# RockChip_RK3588 register map
Vendor: RockChip Electronics Co., Ltd.; Series: RK3588; File version: 0.1
Registers are 32-bit, read-write, no defined reset value unless marked. A register's access mark holds for its fields unless they carry their own. Offsets are from the block's base; [hi:lo] are bit positions.

## CRU (part 6 of 6)
Base 0xFD7C0000
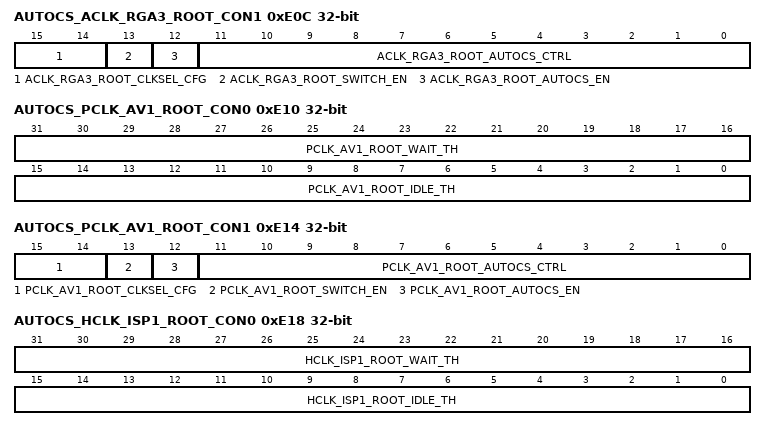
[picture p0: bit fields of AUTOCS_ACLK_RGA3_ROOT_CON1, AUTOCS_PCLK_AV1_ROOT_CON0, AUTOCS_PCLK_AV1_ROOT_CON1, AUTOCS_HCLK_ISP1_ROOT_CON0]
0xE0C AUTOCS_ACLK_RGA3_ROOT_CON1 — Auto clock switch control register 1
  [15:14] ACLK_RGA3_ROOT_CLKSEL_CFG — clksel_cfg Auto switch clock selection.
    0=ORIGINAL_CLK; 1=XIN_OSC0_FUNC_DIV; 2=CLK_RTC_32K
  [13] ACLK_RGA3_ROOT_SWITCH_EN — switch_en
    1=ENABLE (Enable aclk_rga3_root switched to lower frequency when module is inactive.); 0=DISABLE (Disable auto switch function.)
  [12] ACLK_RGA3_ROOT_AUTOCS_EN — autocs_en
    1=ENABLE (Enable aclk_rga3_root switch to lower frequency.); 0=DISABLE
  [11:0] ACLK_RGA3_ROOT_AUTOCS_CTRL — autocs_ctrl. Others: Reserved.
    0xFFF=ENABLE (Enable aclk_rga3_root switch to lower frequency.); 0=DISABLE
0xE10 AUTOCS_PCLK_AV1_ROOT_CON0 — Auto clock switch control register 0
  [31:16] PCLK_AV1_ROOT_WAIT_TH — wait_th. Wait time threshold, measured by original clk.
  [15:0] PCLK_AV1_ROOT_IDLE_TH — idle_th. Idle time threshold, measured by original clk.
0xE14 AUTOCS_PCLK_AV1_ROOT_CON1 — Auto clock switch control register 1
  [15:14] PCLK_AV1_ROOT_CLKSEL_CFG — clksel_cfg Auto switch clock selection.
    0=ORIGINAL_CLK; 1=XIN_OSC0_FUNC_DIV; 2=CLK_RTC_32K
  [13] PCLK_AV1_ROOT_SWITCH_EN — switch_en
    1=ENABLE (Enable pclk_av1_root switched to lower frequency when module is inactive.); 0=DISABLE (Disable auto switch function.)
  [12] PCLK_AV1_ROOT_AUTOCS_EN — autocs_en
    1=ENABLE (Enable pclk_av1_root switch to lower frequency.); 0=DISABLE
  [11:0] PCLK_AV1_ROOT_AUTOCS_CTRL — autocs_ctrl. Others: Reserved.
    0xFFF=ENABLE (Enable pclk_av1_root switch to lower frequency.); 0=DISABLE
0xE18 AUTOCS_HCLK_ISP1_ROOT_CON0 — Auto clock switch control register 0
  [31:16] HCLK_ISP1_ROOT_WAIT_TH — wait_th. Wait time threshold, measured by original clk.
  [15:0] HCLK_ISP1_ROOT_IDLE_TH — idle_th. Idle time threshold, measured by original clk.
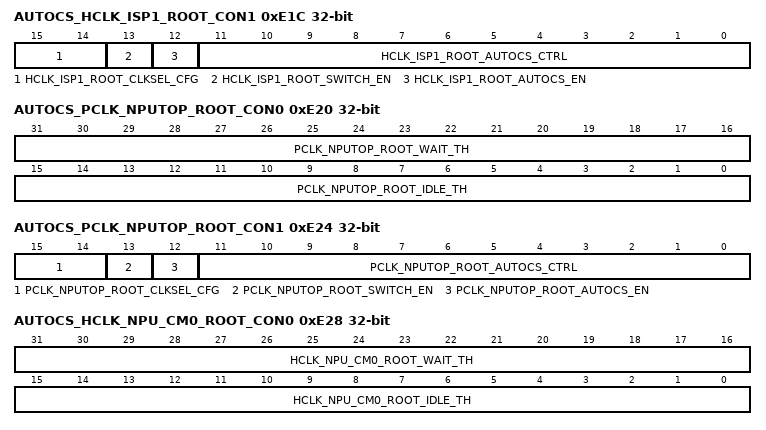
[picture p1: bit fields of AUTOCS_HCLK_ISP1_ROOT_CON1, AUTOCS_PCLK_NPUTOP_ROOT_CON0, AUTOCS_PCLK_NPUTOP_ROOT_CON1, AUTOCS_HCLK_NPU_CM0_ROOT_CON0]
0xE1C AUTOCS_HCLK_ISP1_ROOT_CON1 — Auto clock switch control register 1
  [15:14] HCLK_ISP1_ROOT_CLKSEL_CFG — clksel_cfg Auto switch clock selection.
    0=ORIGINAL_CLK; 1=XIN_OSC0_FUNC_DIV; 2=CLK_RTC_32K
  [13] HCLK_ISP1_ROOT_SWITCH_EN — switch_en
    1=ENABLE (Enable hclk_isp1_root switched to lower frequency when module is inactive.); 0=DISABLE (Disable auto switch function.)
  [12] HCLK_ISP1_ROOT_AUTOCS_EN — autocs_en
    1=ENABLE (Enable hclk_isp1_root switch to lower frequency.); 0=DISABLE
  [11:0] HCLK_ISP1_ROOT_AUTOCS_CTRL — autocs_ctrl. Others: Reserved.
    0xFFF=ENABLE (Enable hclk_isp1_root switch to lower frequency.); 0=DISABLE
0xE20 AUTOCS_PCLK_NPUTOP_ROOT_CON0 — Auto clock switch control register 0
  [31:16] PCLK_NPUTOP_ROOT_WAIT_TH — wait_th. Wait time threshold, measured by original clk.
  [15:0] PCLK_NPUTOP_ROOT_IDLE_TH — idle_th. Idle time threshold, measured by original clk.
0xE24 AUTOCS_PCLK_NPUTOP_ROOT_CON1 — Auto clock switch control register 1
  [15:14] PCLK_NPUTOP_ROOT_CLKSEL_CFG — clksel_cfg Auto switch clock selection.
    0=ORIGINAL_CLK; 1=XIN_OSC0_FUNC_DIV; 2=CLK_RTC_32K
  [13] PCLK_NPUTOP_ROOT_SWITCH_EN — switch_en
    1=ENABLE (Enable pclk_nputop_root switched to lower frequency when module is inactive.); 0=DISABLE (Disable auto switch function.)
  [12] PCLK_NPUTOP_ROOT_AUTOCS_EN — autocs_en
    1=ENABLE (Enable pclk_nputop_root switch to lower frequency.); 0=DISABLE
  [11:0] PCLK_NPUTOP_ROOT_AUTOCS_CTRL — autocs_ctrl. Others: Reserved.
    0xFFF=ENABLE (Enable pclk_nputop_root switch to lower frequency.); 0=DISABLE
0xE28 AUTOCS_HCLK_NPU_CM0_ROOT_CON0 — Auto clock switch control register 0
  [31:16] HCLK_NPU_CM0_ROOT_WAIT_TH — wait_th. Wait time threshold, measured by original clk.
  [15:0] HCLK_NPU_CM0_ROOT_IDLE_TH — idle_th. Idle time threshold, measured by original clk.
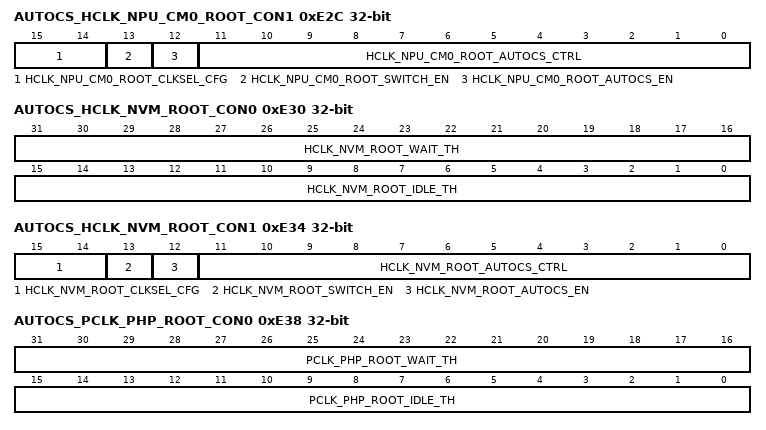
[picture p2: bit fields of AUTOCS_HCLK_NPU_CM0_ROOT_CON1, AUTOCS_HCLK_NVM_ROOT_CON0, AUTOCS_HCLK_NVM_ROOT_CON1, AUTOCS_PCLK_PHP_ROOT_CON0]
0xE2C AUTOCS_HCLK_NPU_CM0_ROOT_CON1 — Auto clock switch control register 1
  [15:14] HCLK_NPU_CM0_ROOT_CLKSEL_CFG — clksel_cfg Auto switch clock selection.
    0=ORIGINAL_CLK; 1=XIN_OSC0_FUNC_DIV; 2=CLK_RTC_32K
  [13] HCLK_NPU_CM0_ROOT_SWITCH_EN — switch_en
    1=ENABLE (Enable hclk_npu_cm0_root switched to lower frequency when module is inactive.); 0=DISABLE (Disable auto switch function.)
  [12] HCLK_NPU_CM0_ROOT_AUTOCS_EN — autocs_en
    1=ENABLE (Enable hclk_npu_cm0_root switch to lower frequency.); 0=DISABLE
  [11:0] HCLK_NPU_CM0_ROOT_AUTOCS_CTRL — autocs_ctrl. Others: Reserved.
    0xFFF=ENABLE (Enable hclk_npu_cm0_root switch to lower frequency.); 0=DISABLE
0xE30 AUTOCS_HCLK_NVM_ROOT_CON0 — Auto clock switch control register 0
  [31:16] HCLK_NVM_ROOT_WAIT_TH — wait_th. Wait time threshold, measured by original clk.
  [15:0] HCLK_NVM_ROOT_IDLE_TH — idle_th. Idle time threshold, measured by original clk.
0xE34 AUTOCS_HCLK_NVM_ROOT_CON1 — Auto clock switch control register 1
  [15:14] HCLK_NVM_ROOT_CLKSEL_CFG — clksel_cfg Auto switch clock selection.
    0=ORIGINAL_CLK; 1=XIN_OSC0_FUNC_DIV; 2=CLK_RTC_32K
  [13] HCLK_NVM_ROOT_SWITCH_EN — switch_en
    1=ENABLE (Enable hclk_nvm_root switched to lower frequency when module is inactive.); 0=DISABLE (Disable auto switch function.)
  [12] HCLK_NVM_ROOT_AUTOCS_EN — autocs_en
    1=ENABLE (Enable hclk_nvm_root switch to lower frequency.); 0=DISABLE
  [11:0] HCLK_NVM_ROOT_AUTOCS_CTRL — autocs_ctrl. Others: Reserved.
    0xFFF=ENABLE (Enable hclk_nvm_root switch to lower frequency.); 0=DISABLE
0xE38 AUTOCS_PCLK_PHP_ROOT_CON0 — Auto clock switch control register 0
  [31:16] PCLK_PHP_ROOT_WAIT_TH — wait_th. Wait time threshold, measured by original clk.
  [15:0] PCLK_PHP_ROOT_IDLE_TH — idle_th. Idle time threshold, measured by original clk.
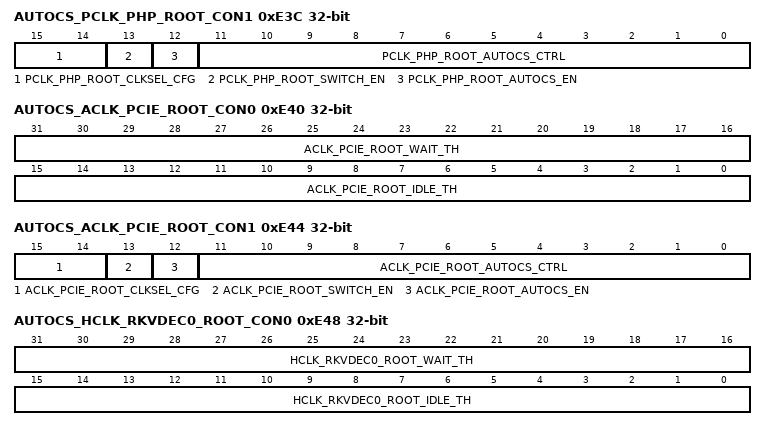
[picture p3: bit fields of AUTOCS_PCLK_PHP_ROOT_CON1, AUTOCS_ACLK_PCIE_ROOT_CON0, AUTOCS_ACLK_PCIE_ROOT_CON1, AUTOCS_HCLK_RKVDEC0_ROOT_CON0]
0xE3C AUTOCS_PCLK_PHP_ROOT_CON1 — Auto clock switch control register 1
  [15:14] PCLK_PHP_ROOT_CLKSEL_CFG — clksel_cfg Auto switch clock selection.
    0=ORIGINAL_CLK; 1=XIN_OSC0_FUNC_DIV; 2=CLK_RTC_32K
  [13] PCLK_PHP_ROOT_SWITCH_EN — switch_en
    1=ENABLE (Enable pclk_php_root switched to lower frequency when module is inactive.); 0=DISABLE (Disable auto switch function.)
  [12] PCLK_PHP_ROOT_AUTOCS_EN — autocs_en
    1=ENABLE (Enable pclk_php_root switch to lower frequency.); 0=DISABLE
  [11:0] PCLK_PHP_ROOT_AUTOCS_CTRL — autocs_ctrl. Others: Reserved.
    0xFFF=ENABLE (Enable pclk_php_root switch to lower frequency.); 0=DISABLE
0xE40 AUTOCS_ACLK_PCIE_ROOT_CON0 — Auto clock switch control register 0
  [31:16] ACLK_PCIE_ROOT_WAIT_TH — wait_th. Wait time threshold, measured by original clk.
  [15:0] ACLK_PCIE_ROOT_IDLE_TH — idle_th. Idle time threshold, measured by original clk.
0xE44 AUTOCS_ACLK_PCIE_ROOT_CON1 — Auto clock switch control register 1
  [15:14] ACLK_PCIE_ROOT_CLKSEL_CFG — clksel_cfg Auto switch clock selection.
    0=ORIGINAL_CLK; 1=XIN_OSC0_FUNC_DIV; 2=CLK_RTC_32K
  [13] ACLK_PCIE_ROOT_SWITCH_EN — switch_en
    1=ENABLE (Enable aclk_pcie_root switched to lower frequency when module is inactive.); 0=DISABLE (Disable auto switch function.)
  [12] ACLK_PCIE_ROOT_AUTOCS_EN — autocs_en
    1=ENABLE (Enable aclk_pcie_root switch to lower frequency.); 0=DISABLE
  [11:0] ACLK_PCIE_ROOT_AUTOCS_CTRL — autocs_ctrl. Others: Reserved.
    0xFFF=ENABLE (Enable aclk_pcie_root switch to lower frequency.); 0=DISABLE
0xE48 AUTOCS_HCLK_RKVDEC0_ROOT_CON0 — Auto clock switch control register 0CLK_PCIE_ROOT_CLKSEL_CFG ; clksel_cfg Auto switch clock selection.
  [31:16] HCLK_RKVDEC0_ROOT_WAIT_TH — wait_th. Wait time threshold, measured by original clk.
  [15:0] HCLK_RKVDEC0_ROOT_IDLE_TH — idle_th. Idle time threshold, measured by original clk.
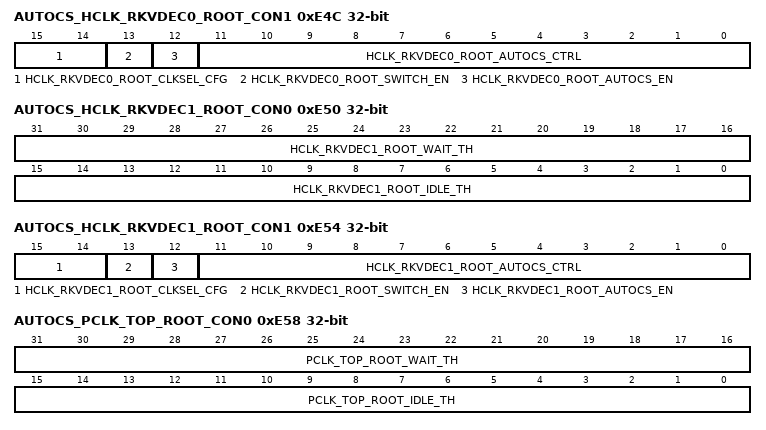
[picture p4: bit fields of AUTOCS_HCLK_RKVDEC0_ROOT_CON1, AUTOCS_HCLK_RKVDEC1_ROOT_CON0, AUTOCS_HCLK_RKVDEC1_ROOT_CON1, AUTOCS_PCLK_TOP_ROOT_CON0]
0xE4C AUTOCS_HCLK_RKVDEC0_ROOT_CON1 — Auto clock switch control register 1
  [15:14] HCLK_RKVDEC0_ROOT_CLKSEL_CFG — clksel_cfg Auto switch clock selection.
    0=ORIGINAL_CLK; 1=XIN_OSC0_FUNC_DIV; 2=CLK_RTC_32K
  [13] HCLK_RKVDEC0_ROOT_SWITCH_EN — switch_en
    1=ENABLE (Enable hclk_rkvdec0_root switched to lower frequency when module is inactive.); 0=DISABLE (Disable auto switch function.)
  [12] HCLK_RKVDEC0_ROOT_AUTOCS_EN — autocs_en
    1=ENABLE (Enable hclk_rkvdec0_root switch to lower frequency.); 0=DISABLE
  [11:0] HCLK_RKVDEC0_ROOT_AUTOCS_CTRL — autocs_ctrl. Others: Reserved.
    0xFFF=ENABLE (Enable hclk_rkvdec0_root switch to lower frequency.); 0=DISABLE
0xE50 AUTOCS_HCLK_RKVDEC1_ROOT_CON0 — Auto clock switch control register 0
  [31:16] HCLK_RKVDEC1_ROOT_WAIT_TH — wait_th. Wait time threshold, measured by original clk.
  [15:0] HCLK_RKVDEC1_ROOT_IDLE_TH — idle_th. Idle time threshold, measured by original clk.
0xE54 AUTOCS_HCLK_RKVDEC1_ROOT_CON1 — Auto clock switch control register 1
  [15:14] HCLK_RKVDEC1_ROOT_CLKSEL_CFG — clksel_cfg Auto switch clock selection.
    0=ORIGINAL_CLK; 1=XIN_OSC0_FUNC_DIV; 2=CLK_RTC_32K
  [13] HCLK_RKVDEC1_ROOT_SWITCH_EN — switch_en
    1=ENABLE (Enable hclk_rkvdec1_root switched to lower frequency when module is inactive.); 0=DISABLE (Disable auto switch function.)
  [12] HCLK_RKVDEC1_ROOT_AUTOCS_EN — autocs_en
    1=ENABLE (Enable hclk_rkvdec1_root switch to lower frequency.); 0=DISABLE
  [11:0] HCLK_RKVDEC1_ROOT_AUTOCS_CTRL — autocs_ctrl. Others: Reserved.
    0xFFF=ENABLE (Enable hclk_rkvdec1_root switch to lower frequency.); 0=DISABLE
0xE58 AUTOCS_PCLK_TOP_ROOT_CON0 — Auto clock switch control register 0
  [31:16] PCLK_TOP_ROOT_WAIT_TH — wait_th. Wait time threshold, measured by original clk.
  [15:0] PCLK_TOP_ROOT_IDLE_TH — idle_th. Idle time threshold, measured by original clk.
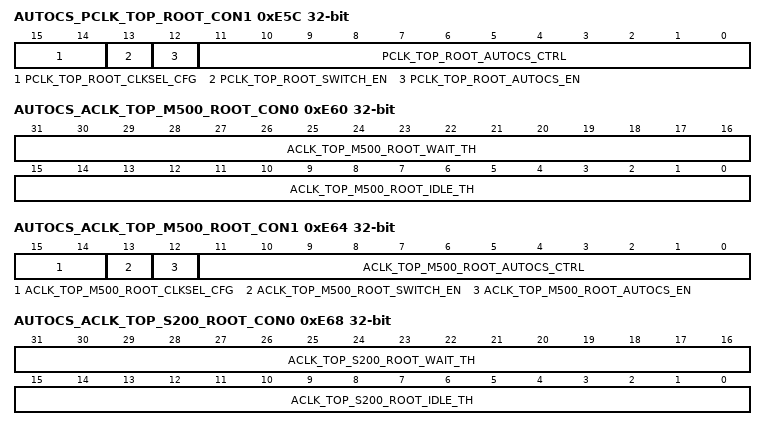
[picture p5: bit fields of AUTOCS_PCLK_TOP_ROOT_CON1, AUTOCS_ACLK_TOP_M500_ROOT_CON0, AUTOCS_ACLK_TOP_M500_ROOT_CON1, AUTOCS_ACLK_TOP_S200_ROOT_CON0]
0xE5C AUTOCS_PCLK_TOP_ROOT_CON1 — Auto clock switch control register 1
  [15:14] PCLK_TOP_ROOT_CLKSEL_CFG — clksel_cfg Auto switch clock selection.
    0=ORIGINAL_CLK; 1=XIN_OSC0_FUNC_DIV; 2=CLK_RTC_32K
  [13] PCLK_TOP_ROOT_SWITCH_EN — switch_en
    1=ENABLE (Enable pclk_top_root switched to lower frequency when module is inactive.); 0=DISABLE (Disable auto switch function.)
  [12] PCLK_TOP_ROOT_AUTOCS_EN — autocs_en
    1=ENABLE (Enable pclk_top_root switch to lower frequency.); 0=DISABLE
  [11:0] PCLK_TOP_ROOT_AUTOCS_CTRL — autocs_ctrl. Others: Reserved.
    0xFFF=ENABLE (Enable pclk_top_root switch to lower frequency.); 0=DISABLE
0xE60 AUTOCS_ACLK_TOP_M500_ROOT_CON0 — Auto clock switch control register 0
  [31:16] ACLK_TOP_M500_ROOT_WAIT_TH — wait_th. Wait time threshold, measured by original clk.
  [15:0] ACLK_TOP_M500_ROOT_IDLE_TH — idle_th. Idle time threshold, measured by original clk.
0xE64 AUTOCS_ACLK_TOP_M500_ROOT_CON1 — Auto clock switch control register 1
  [15:14] ACLK_TOP_M500_ROOT_CLKSEL_CFG — clksel_cfg Auto switch clock selection.
    0=ORIGINAL_CLK; 1=XIN_OSC0_FUNC_DIV; 2=CLK_RTC_32K
  [13] ACLK_TOP_M500_ROOT_SWITCH_EN — switch_en
    1=ENABLE (Enable aclk_top_m500_root switched to lower frequency when module is inactive.); 0=DISABLE (Disable auto switch function.)
  [12] ACLK_TOP_M500_ROOT_AUTOCS_EN — autocs_en
    1=ENABLE (Enable aclk_top_m500_root switch to lower frequency.); 0=DISABLE
  [11:0] ACLK_TOP_M500_ROOT_AUTOCS_CTRL — autocs_ctrl. Others: Reserved.
    0xFFF=ENABLE (Enable aclk_top_m500_root switch to lower frequency.); 0=DISABLE
0xE68 AUTOCS_ACLK_TOP_S200_ROOT_CON0 — Auto clock switch control register 0
  [31:16] ACLK_TOP_S200_ROOT_WAIT_TH — wait_th. Wait time threshold, measured by original clk.
  [15:0] ACLK_TOP_S200_ROOT_IDLE_TH — idle_th. Idle time threshold, measured by original clk.
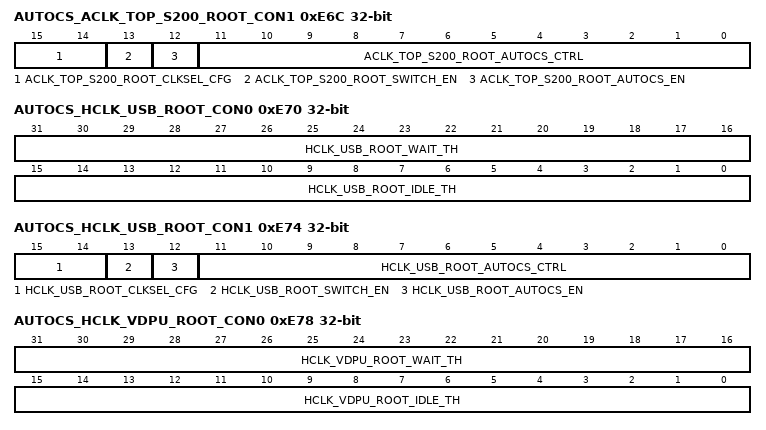
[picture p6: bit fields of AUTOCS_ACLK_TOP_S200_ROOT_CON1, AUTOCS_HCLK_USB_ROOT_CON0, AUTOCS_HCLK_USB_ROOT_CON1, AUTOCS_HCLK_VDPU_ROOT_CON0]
0xE6C AUTOCS_ACLK_TOP_S200_ROOT_CON1 — Auto clock switch control register 1
  [15:14] ACLK_TOP_S200_ROOT_CLKSEL_CFG — clksel_cfg Auto switch clock selection.
    0=ORIGINAL_CLK; 1=XIN_OSC0_FUNC_DIV; 2=CLK_RTC_32K
  [13] ACLK_TOP_S200_ROOT_SWITCH_EN — switch_en
    1=ENABLE (Enable aclk_top_s200_root switched to lower frequency when module is inactive.); 0=DISABLE (Disable auto switch function.)
  [12] ACLK_TOP_S200_ROOT_AUTOCS_EN — autocs_en
    1=ENABLE (Enable aclk_top_s200_root switch to lower frequency.); 0=DISABLE
  [11:0] ACLK_TOP_S200_ROOT_AUTOCS_CTRL — autocs_ctrl. Others: Reserved.
    0xFFF=ENABLE (Enable aclk_top_s200_root switch to lower frequency.); 0=DISABLE
0xE70 AUTOCS_HCLK_USB_ROOT_CON0 — Auto clock switch control register 0
  [31:16] HCLK_USB_ROOT_WAIT_TH — wait_th. Wait time threshold, measured by original clk.
  [15:0] HCLK_USB_ROOT_IDLE_TH — idle_th. Idle time threshold, measured by original clk.
0xE74 AUTOCS_HCLK_USB_ROOT_CON1 — Auto clock switch control register 1
  [15:14] HCLK_USB_ROOT_CLKSEL_CFG — clksel_cfg Auto switch clock selection.
    0=ORIGINAL_CLK; 1=XIN_OSC0_FUNC_DIV; 2=CLK_RTC_32K
  [13] HCLK_USB_ROOT_SWITCH_EN — switch_en
    1=ENABLE (Enable hclk_usb_root switched to lower frequency when module is inactive.); 0=DISABLE (Disable auto switch function.)
  [12] HCLK_USB_ROOT_AUTOCS_EN — autocs_en
    1=ENABLE (Enable hclk_usb_root switch to lower frequency.); 0=DISABLE
  [11:0] HCLK_USB_ROOT_AUTOCS_CTRL — autocs_ctrl. Others: Reserved.
    0xFFF=ENABLE (Enable hclk_usb_root switch to lower frequency.); 0=DISABLE
0xE78 AUTOCS_HCLK_VDPU_ROOT_CON0 — Auto clock switch control register 0
  [31:16] HCLK_VDPU_ROOT_WAIT_TH — wait_th. Wait time threshold, measured by original clk.
  [15:0] HCLK_VDPU_ROOT_IDLE_TH — idle_th. Idle time threshold, measured by original clk.
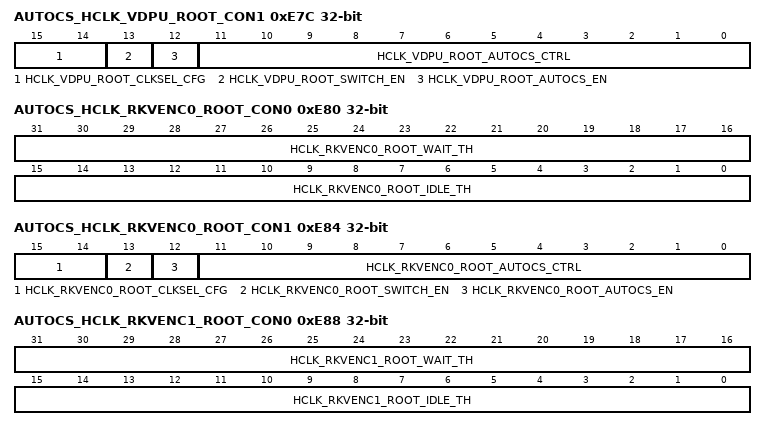
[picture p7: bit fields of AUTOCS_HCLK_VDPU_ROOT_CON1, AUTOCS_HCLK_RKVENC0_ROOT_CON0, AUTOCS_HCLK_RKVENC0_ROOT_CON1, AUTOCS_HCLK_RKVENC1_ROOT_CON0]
0xE7C AUTOCS_HCLK_VDPU_ROOT_CON1 — Auto clock switch control register 1
  [15:14] HCLK_VDPU_ROOT_CLKSEL_CFG — clksel_cfg Auto switch clock selection.
    0=ORIGINAL_CLK; 1=XIN_OSC0_FUNC_DIV; 2=CLK_RTC_32K
  [13] HCLK_VDPU_ROOT_SWITCH_EN — switch_en
    1=ENABLE (Enable hclk_vdpu_root switched to lower frequency when module is inactive.); 0=DISABLE (Disable auto switch function.)
  [12] HCLK_VDPU_ROOT_AUTOCS_EN — autocs_en
    1=ENABLE (Enable hclk_vdpu_root switch to lower frequency.); 0=DISABLE
  [11:0] HCLK_VDPU_ROOT_AUTOCS_CTRL — autocs_ctrl. Others: Reserved.
    0xFFF=ENABLE (Enable hclk_vdpu_root switch to lower frequency.); 0=DISABLE
0xE80 AUTOCS_HCLK_RKVENC0_ROOT_CON0 — Auto clock switch control register 0
  [31:16] HCLK_RKVENC0_ROOT_WAIT_TH — wait_th. Wait time threshold, measured by original clk.
  [15:0] HCLK_RKVENC0_ROOT_IDLE_TH — idle_th. Idle time threshold, measured by original clk.
0xE84 AUTOCS_HCLK_RKVENC0_ROOT_CON1 — Auto clock switch control register 1
  [15:14] HCLK_RKVENC0_ROOT_CLKSEL_CFG — clksel_cfg Auto switch clock selection.
    0=ORIGINAL_CLK; 1=XIN_OSC0_FUNC_DIV; 2=CLK_RTC_32K
  [13] HCLK_RKVENC0_ROOT_SWITCH_EN — switch_en
    1=ENABLE (Enable hclk_rkvenc0_root switched to lower frequency when module is inactive.); 0=DISABLE (Disable auto switch function.)
  [12] HCLK_RKVENC0_ROOT_AUTOCS_EN — autocs_en
    1=ENABLE (Enable hclk_rkvenc0_root switch to lower frequency.); 0=DISABLE
  [11:0] HCLK_RKVENC0_ROOT_AUTOCS_CTRL — autocs_ctrl. Others: Reserved.
    0xFFF=ENABLE (Enable hclk_rkvenc0_root switch to lower frequency.); 0=DISABLE
0xE88 AUTOCS_HCLK_RKVENC1_ROOT_CON0 — Auto clock switch control register 0
  [31:16] HCLK_RKVENC1_ROOT_WAIT_TH — wait_th. Wait time threshold, measured by original clk.
  [15:0] HCLK_RKVENC1_ROOT_IDLE_TH — idle_th. Idle time threshold, measured by original clk.
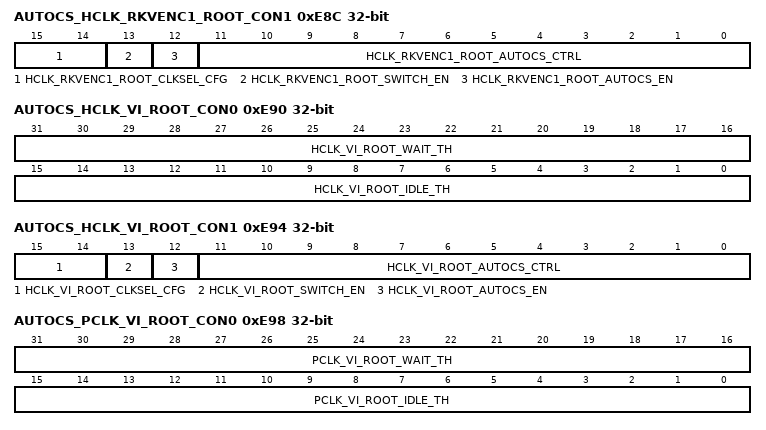
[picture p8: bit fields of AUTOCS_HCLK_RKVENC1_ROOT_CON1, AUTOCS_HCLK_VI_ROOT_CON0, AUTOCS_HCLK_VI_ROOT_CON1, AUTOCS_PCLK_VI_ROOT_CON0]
0xE8C AUTOCS_HCLK_RKVENC1_ROOT_CON1 — Auto clock switch control register 1
  [15:14] HCLK_RKVENC1_ROOT_CLKSEL_CFG — clksel_cfg Auto switch clock selection.
    0=ORIGINAL_CLK; 1=XIN_OSC0_FUNC_DIV; 2=CLK_RTC_32K
  [13] HCLK_RKVENC1_ROOT_SWITCH_EN — switch_en
    1=ENABLE (Enable hclk_rkvenc1_root switched to lower frequency when module is inactive.); 0=DISABLE (Disable auto switch function.)
  [12] HCLK_RKVENC1_ROOT_AUTOCS_EN — autocs_en
    1=ENABLE (Enable hclk_rkvenc1_root switch to lower frequency.); 0=DISABLE
  [11:0] HCLK_RKVENC1_ROOT_AUTOCS_CTRL — autocs_ctrl. Others: Reserved.
    0xFFF=ENABLE (Enable hclk_rkvenc1_root switch to lower frequency.); 0=DISABLE
0xE90 AUTOCS_HCLK_VI_ROOT_CON0 — Auto clock switch control register 0
  [31:16] HCLK_VI_ROOT_WAIT_TH — wait_th. Wait time threshold, measured by original clk.
  [15:0] HCLK_VI_ROOT_IDLE_TH — idle_th. Idle time threshold, measured by original clk.
0xE94 AUTOCS_HCLK_VI_ROOT_CON1 — Auto clock switch control register 1
  [15:14] HCLK_VI_ROOT_CLKSEL_CFG — clksel_cfg Auto switch clock selection.
    0=ORIGINAL_CLK; 1=XIN_OSC0_FUNC_DIV; 2=CLK_RTC_32K
  [13] HCLK_VI_ROOT_SWITCH_EN — switch_en
    1=ENABLE (Enable hclk_vi_root switched to lower frequency when module is inactive.); 0=DISABLE (Disable auto switch function.)
  [12] HCLK_VI_ROOT_AUTOCS_EN — autocs_en
    1=ENABLE (Enable hclk_vi_root switch to lower frequency.); 0=DISABLE
  [11:0] HCLK_VI_ROOT_AUTOCS_CTRL — autocs_ctrl. Others: Reserved.
    0xFFF=ENABLE (Enable hclk_vi_root switch to lower frequency.); 0=DISABLE
0xE98 AUTOCS_PCLK_VI_ROOT_CON0 — Auto clock switch control register 0
  [31:16] PCLK_VI_ROOT_WAIT_TH — wait_th. Wait time threshold, measured by original clk.
  [15:0] PCLK_VI_ROOT_IDLE_TH — idle_th. Idle time threshold, measured by original clk.
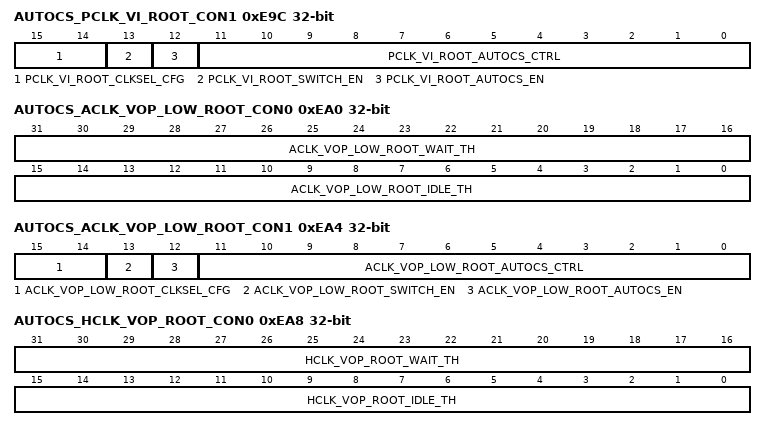
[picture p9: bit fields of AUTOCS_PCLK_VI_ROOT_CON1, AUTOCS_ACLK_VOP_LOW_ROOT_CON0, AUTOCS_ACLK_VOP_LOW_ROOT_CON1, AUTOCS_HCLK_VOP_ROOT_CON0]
0xE9C AUTOCS_PCLK_VI_ROOT_CON1 — Auto clock switch control register 1
  [15:14] PCLK_VI_ROOT_CLKSEL_CFG — clksel_cfg Auto switch clock selection.
    0=ORIGINAL_CLK; 1=XIN_OSC0_FUNC_DIV; 2=CLK_RTC_32K
  [13] PCLK_VI_ROOT_SWITCH_EN — switch_en
    1=ENABLE (Enable pclk_vi_root switched to lower frequency when module is inactive.); 0=DISABLE (Disable auto switch function.)
  [12] PCLK_VI_ROOT_AUTOCS_EN — autocs_en
    1=ENABLE (Enable pclk_vi_root switch to lower frequency.); 0=DISABLE
  [11:0] PCLK_VI_ROOT_AUTOCS_CTRL — autocs_ctrl. Others: Reserved.
    0xFFF=ENABLE (Enable pclk_vi_root switch to lower frequency.); 0=DISABLE
0xEA0 AUTOCS_ACLK_VOP_LOW_ROOT_CON0 — Auto clock switch control register 0
  [31:16] ACLK_VOP_LOW_ROOT_WAIT_TH — wait_th. Wait time threshold, measured by original clk.
  [15:0] ACLK_VOP_LOW_ROOT_IDLE_TH — idle_th. Idle time threshold, measured by original clk.
0xEA4 AUTOCS_ACLK_VOP_LOW_ROOT_CON1 — Auto clock switch control register 1
  [15:14] ACLK_VOP_LOW_ROOT_CLKSEL_CFG — clksel_cfg Auto switch clock selection.
    0=ORIGINAL_CLK; 1=XIN_OSC0_FUNC_DIV; 2=CLK_RTC_32K
  [13] ACLK_VOP_LOW_ROOT_SWITCH_EN — switch_en
    1=ENABLE (Enable aclk_vop_low_root switched to lower frequency when module is inactive.); 0=DISABLE (Disable auto switch function.)
  [12] ACLK_VOP_LOW_ROOT_AUTOCS_EN — autocs_en
    1=ENABLE (Enable aclk_vop_low_root switch to lower frequency.); 0=DISABLE
  [11:0] ACLK_VOP_LOW_ROOT_AUTOCS_CTRL — autocs_ctrl. Others: Reserved.
    0xFFF=ENABLE (Enable aclk_vop_low_root switch to lower frequency.); 0=DISABLE
0xEA8 AUTOCS_HCLK_VOP_ROOT_CON0 — Auto clock switch control register 0
  [31:16] HCLK_VOP_ROOT_WAIT_TH — wait_th. Wait time threshold, measured by original clk.
  [15:0] HCLK_VOP_ROOT_IDLE_TH — idle_th. Idle time threshold, measured by original clk.
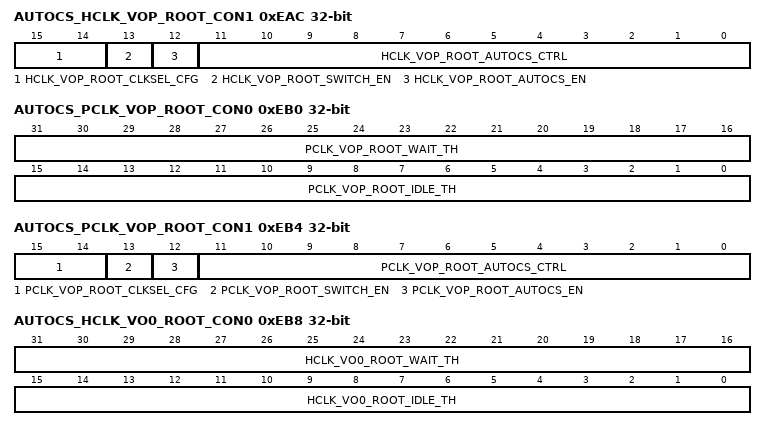
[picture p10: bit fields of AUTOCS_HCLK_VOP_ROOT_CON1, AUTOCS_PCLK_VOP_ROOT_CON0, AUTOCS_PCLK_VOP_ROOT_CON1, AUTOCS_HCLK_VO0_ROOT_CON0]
0xEAC AUTOCS_HCLK_VOP_ROOT_CON1 — Auto clock switch control register 1
  [15:14] HCLK_VOP_ROOT_CLKSEL_CFG — clksel_cfg Auto switch clock selection.
    0=ORIGINAL_CLK; 1=XIN_OSC0_FUNC_DIV; 2=CLK_RTC_32K
  [13] HCLK_VOP_ROOT_SWITCH_EN — switch_en
    1=ENABLE (Enable hclk_vop_root switched to lower frequency when module is inactive.); 0=DISABLE (Disable auto switch function.)
  [12] HCLK_VOP_ROOT_AUTOCS_EN — autocs_en
    1=ENABLE (Enable hclk_vop_root switch to lower frequency.); 0=DISABLE
  [11:0] HCLK_VOP_ROOT_AUTOCS_CTRL — autocs_ctrl. Others: Reserved.
    0xFFF=ENABLE (Enable hclk_vop_root switch to lower frequency.); 0=DISABLE
0xEB0 AUTOCS_PCLK_VOP_ROOT_CON0 — Auto clock switch control register 0
  [31:16] PCLK_VOP_ROOT_WAIT_TH — wait_th. Wait time threshold, measured by original clk.
  [15:0] PCLK_VOP_ROOT_IDLE_TH — idle_th. Idle time threshold, measured by original clk.
0xEB4 AUTOCS_PCLK_VOP_ROOT_CON1 — Auto clock switch control register 1
  [15:14] PCLK_VOP_ROOT_CLKSEL_CFG — clksel_cfg Auto switch clock selection.
    0=ORIGINAL_CLK; 1=XIN_OSC0_FUNC_DIV; 2=CLK_RTC_32K
  [13] PCLK_VOP_ROOT_SWITCH_EN — switch_en
    1=ENABLE (Enable pclk_vop_root switched to lower frequency when module is inactive.); 0=DISABLE (Disable auto switch function.)
  [12] PCLK_VOP_ROOT_AUTOCS_EN — autocs_en
    1=ENABLE (Enable pclk_vop_root switch to lower frequency.); 0=DISABLE
  [11:0] PCLK_VOP_ROOT_AUTOCS_CTRL — autocs_ctrl. Others: Reserved.
    0xFFF=ENABLE (Enable pclk_vop_root switch to lower frequency.); 0=DISABLE
0xEB8 AUTOCS_HCLK_VO0_ROOT_CON0 — Auto clock switch control register 0
  [31:16] HCLK_VO0_ROOT_WAIT_TH — wait_th. Wait time threshold, measured by original clk.
  [15:0] HCLK_VO0_ROOT_IDLE_TH — idle_th. Idle time threshold, measured by original clk.
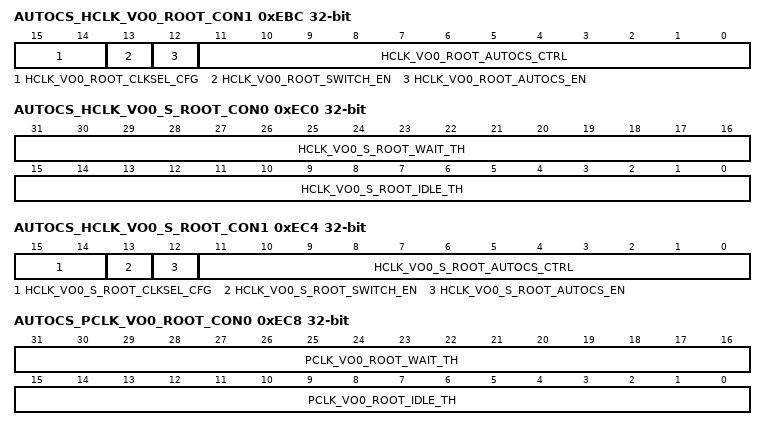
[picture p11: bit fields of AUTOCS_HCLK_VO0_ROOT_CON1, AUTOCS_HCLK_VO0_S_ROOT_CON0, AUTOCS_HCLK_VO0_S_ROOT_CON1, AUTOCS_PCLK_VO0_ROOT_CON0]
0xEBC AUTOCS_HCLK_VO0_ROOT_CON1 — Auto clock switch control register 1
  [15:14] HCLK_VO0_ROOT_CLKSEL_CFG — clksel_cfg Auto switch clock selection.
    0=ORIGINAL_CLK; 1=XIN_OSC0_FUNC_DIV; 2=CLK_RTC_32K
  [13] HCLK_VO0_ROOT_SWITCH_EN — switch_en
    1=ENABLE (Enable hclk_vo0_root switched to lower frequency when module is inactive.); 0=DISABLE (Disable auto switch function.)
  [12] HCLK_VO0_ROOT_AUTOCS_EN — autocs_en
    1=ENABLE (Enable hclk_vo0_root switch to lower frequency.); 0=DISABLE
  [11:0] HCLK_VO0_ROOT_AUTOCS_CTRL — autocs_ctrl. Others: Reserved.
    0xFFF=ENABLE (Enable hclk_vo0_root switch to lower frequency.); 0=DISABLE
0xEC0 AUTOCS_HCLK_VO0_S_ROOT_CON0 — Auto clock switch control register 0
  [31:16] HCLK_VO0_S_ROOT_WAIT_TH — wait_th. Wait time threshold, measured by original clk.
  [15:0] HCLK_VO0_S_ROOT_IDLE_TH — idle_th. Idle time threshold, measured by original clk.
0xEC4 AUTOCS_HCLK_VO0_S_ROOT_CON1 — Auto clock switch control register 1
  [15:14] HCLK_VO0_S_ROOT_CLKSEL_CFG — clksel_cfg Auto switch clock selection.
    0=ORIGINAL_CLK; 1=XIN_OSC0_FUNC_DIV; 2=CLK_RTC_32K
  [13] HCLK_VO0_S_ROOT_SWITCH_EN — switch_en
    1=ENABLE (Enable hclk_vo0_s_root switched to lower frequency when module is inactive.); 0=DISABLE (Disable auto switch function.)
  [12] HCLK_VO0_S_ROOT_AUTOCS_EN — autocs_en
    1=ENABLE (Enable hclk_vo0_s_root switch to lower frequency.); 0=DISABLE
  [11:0] HCLK_VO0_S_ROOT_AUTOCS_CTRL — autocs_ctrl. Others: Reserved.
    0xFFF=ENABLE (Enable hclk_vo0_s_root switch to lower frequency.); 0=DISABLE
0xEC8 AUTOCS_PCLK_VO0_ROOT_CON0 — Auto clock switch control register 0
  [31:16] PCLK_VO0_ROOT_WAIT_TH — wait_th. Wait time threshold, measured by original clk.
  [15:0] PCLK_VO0_ROOT_IDLE_TH — idle_th. Idle time threshold, measured by original clk.
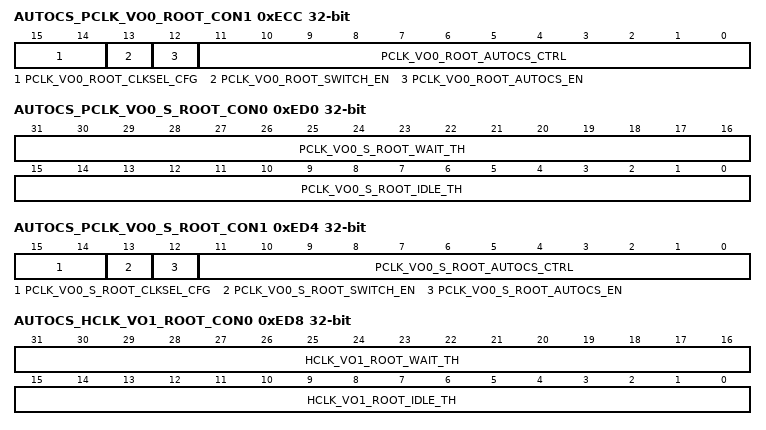
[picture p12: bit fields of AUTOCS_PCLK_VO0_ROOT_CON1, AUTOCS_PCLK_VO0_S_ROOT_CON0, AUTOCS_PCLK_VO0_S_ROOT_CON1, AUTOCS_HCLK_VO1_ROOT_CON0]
0xECC AUTOCS_PCLK_VO0_ROOT_CON1 — Auto clock switch control register 1
  [15:14] PCLK_VO0_ROOT_CLKSEL_CFG — clksel_cfg Auto switch clock selection.
    0=ORIGINAL_CLK; 1=XIN_OSC0_FUNC_DIV; 2=CLK_RTC_32K
  [13] PCLK_VO0_ROOT_SWITCH_EN — switch_en
    1=ENABLE (Enable pclk_vo0_root switched to lower frequency when module is inactive.); 0=DISABLE (Disable auto switch function.)
  [12] PCLK_VO0_ROOT_AUTOCS_EN — autocs_en
    1=ENABLE (Enable pclk_vo0_root switch to lower frequency.); 0=DISABLE
  [11:0] PCLK_VO0_ROOT_AUTOCS_CTRL — autocs_ctrl. Others: Reserved.
    0xFFF=ENABLE (Enable pclk_vo0_root switch to lower frequency.); 0=DISABLE
0xED0 AUTOCS_PCLK_VO0_S_ROOT_CON0 — Auto clock switch control register 0
  [31:16] PCLK_VO0_S_ROOT_WAIT_TH — wait_th. Wait time threshold, measured by original clk.
  [15:0] PCLK_VO0_S_ROOT_IDLE_TH — idle_th. Idle time threshold, measured by original clk.
0xED4 AUTOCS_PCLK_VO0_S_ROOT_CON1 — Auto clock switch control register 1
  [15:14] PCLK_VO0_S_ROOT_CLKSEL_CFG — clksel_cfg Auto switch clock selection.
    0=ORIGINAL_CLK; 1=XIN_OSC0_FUNC_DIV; 2=CLK_RTC_32K
  [13] PCLK_VO0_S_ROOT_SWITCH_EN — switch_en
    1=ENABLE (Enable pclk_vo0_s_root switched to lower frequency when module is inactive.); 0=DISABLE (Disable auto switch function.)
  [12] PCLK_VO0_S_ROOT_AUTOCS_EN — autocs_en
    1=ENABLE (Enable pclk_vo0_s_root switch to lower frequency.); 0=DISABLE
  [11:0] PCLK_VO0_S_ROOT_AUTOCS_CTRL — autocs_ctrl. Others: Reserved.
    0xFFF=ENABLE (Enable pclk_vo0_s_root switch to lower frequency.); 0=DISABLE
0xED8 AUTOCS_HCLK_VO1_ROOT_CON0 — Auto clock switch control register 0
  [31:16] HCLK_VO1_ROOT_WAIT_TH — wait_th. Wait time threshold, measured by original clk.
  [15:0] HCLK_VO1_ROOT_IDLE_TH — idle_th. Idle time threshold, measured by original clk.
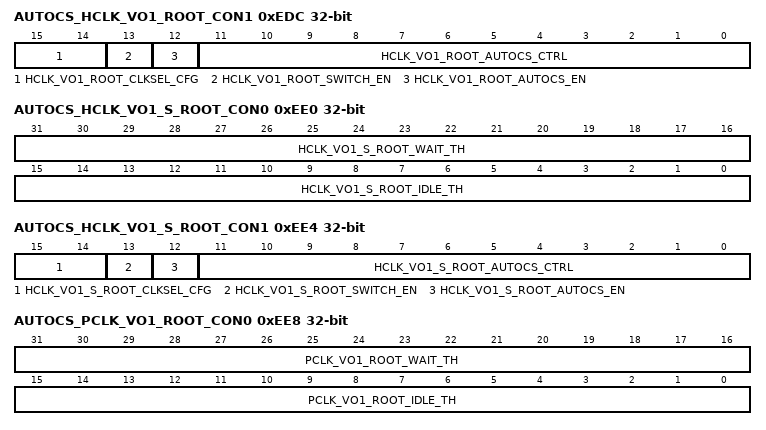
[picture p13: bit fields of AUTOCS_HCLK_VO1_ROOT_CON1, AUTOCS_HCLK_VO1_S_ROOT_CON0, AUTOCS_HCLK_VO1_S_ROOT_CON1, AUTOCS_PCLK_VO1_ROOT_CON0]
0xEDC AUTOCS_HCLK_VO1_ROOT_CON1 — Auto clock switch control register 1
  [15:14] HCLK_VO1_ROOT_CLKSEL_CFG — clksel_cfg Auto switch clock selection.
    0=ORIGINAL_CLK; 1=XIN_OSC0_FUNC_DIV; 2=CLK_RTC_32K
  [13] HCLK_VO1_ROOT_SWITCH_EN — switch_en
    1=ENABLE (Enable hclk_vo1_root switched to lower frequency when module is inactive.); 0=DISABLE (Disable auto switch function.)
  [12] HCLK_VO1_ROOT_AUTOCS_EN — autocs_en
    1=ENABLE (Enable hclk_vo1_root switch to lower frequency.); 0=DISABLE
  [11:0] HCLK_VO1_ROOT_AUTOCS_CTRL — autocs_ctrl. Others: Reserved.
    0xFFF=ENABLE (Enable hclk_vo1_root switch to lower frequency.); 0=DISABLE
0xEE0 AUTOCS_HCLK_VO1_S_ROOT_CON0 — Auto clock switch control register 0
  [31:16] HCLK_VO1_S_ROOT_WAIT_TH — wait_th. Wait time threshold, measured by original clk.
  [15:0] HCLK_VO1_S_ROOT_IDLE_TH — idle_th. Idle time threshold, measured by original clk.
0xEE4 AUTOCS_HCLK_VO1_S_ROOT_CON1 — Auto clock switch control register 1
  [15:14] HCLK_VO1_S_ROOT_CLKSEL_CFG — clksel_cfg Auto switch clock selection.
    0=ORIGINAL_CLK; 1=XIN_OSC0_FUNC_DIV; 2=CLK_RTC_32K
  [13] HCLK_VO1_S_ROOT_SWITCH_EN — switch_en
    1=ENABLE (Enable hclk_vo1_s_root switched to lower frequency when module is inactive.); 0=DISABLE (Disable auto switch function.)
  [12] HCLK_VO1_S_ROOT_AUTOCS_EN — autocs_en
    1=ENABLE (Enable hclk_vo1_s_root switch to lower frequency.); 0=DISABLE
  [11:0] HCLK_VO1_S_ROOT_AUTOCS_CTRL — autocs_ctrl. Others: Reserved.
    0xFFF=ENABLE (Enable hclk_vo1_s_root switch to lower frequency.); 0=DISABLE
0xEE8 AUTOCS_PCLK_VO1_ROOT_CON0 — Auto clock switch control register 0
  [31:16] PCLK_VO1_ROOT_WAIT_TH — wait_th. Wait time threshold, measured by original clk.
  [15:0] PCLK_VO1_ROOT_IDLE_TH — idle_th. Idle time threshold, measured by original clk.
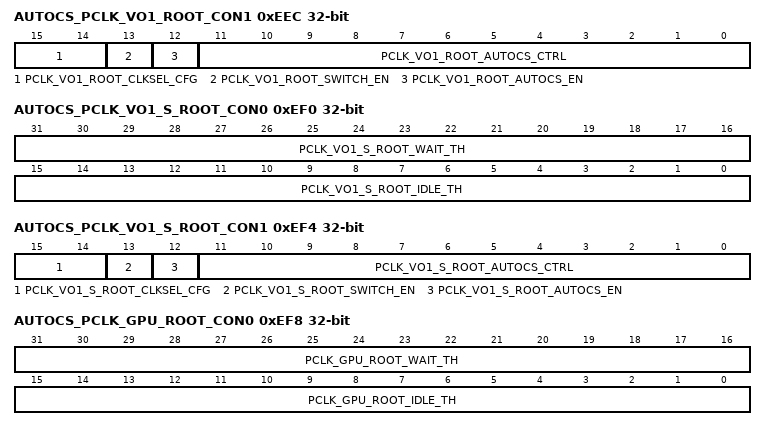
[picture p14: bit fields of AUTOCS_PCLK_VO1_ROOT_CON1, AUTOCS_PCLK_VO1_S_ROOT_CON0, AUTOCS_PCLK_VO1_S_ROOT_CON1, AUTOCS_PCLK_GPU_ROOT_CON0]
0xEEC AUTOCS_PCLK_VO1_ROOT_CON1 — Auto clock switch control register 1
  [15:14] PCLK_VO1_ROOT_CLKSEL_CFG — clksel_cfg Auto switch clock selection.
    0=ORIGINAL_CLK; 1=XIN_OSC0_FUNC_DIV; 2=CLK_RTC_32K
  [13] PCLK_VO1_ROOT_SWITCH_EN — switch_en
    1=ENABLE (Enable pclk_vo1_root switched to lower frequency when module is inactive.); 0=DISABLE (Disable auto switch function.)
  [12] PCLK_VO1_ROOT_AUTOCS_EN — autocs_en
    1=ENABLE (Enable pclk_vo1_root switch to lower frequency.); 0=DISABLE
  [11:0] PCLK_VO1_ROOT_AUTOCS_CTRL — autocs_ctrl. Others: Reserved.
    0xFFF=ENABLE (Enable pclk_vo1_root switch to lower frequency.); 0=DISABLE
0xEF0 AUTOCS_PCLK_VO1_S_ROOT_CON0 — Auto clock switch control register 0
  [31:16] PCLK_VO1_S_ROOT_WAIT_TH — wait_th. Wait time threshold, measured by original clk.
  [15:0] PCLK_VO1_S_ROOT_IDLE_TH — idle_th. Idle time threshold, measured by original clk.
0xEF4 AUTOCS_PCLK_VO1_S_ROOT_CON1 — Auto clock switch control register 1
  [15:14] PCLK_VO1_S_ROOT_CLKSEL_CFG — clksel_cfg Auto switch clock selection.
    0=ORIGINAL_CLK; 1=XIN_OSC0_FUNC_DIV; 2=CLK_RTC_32K
  [13] PCLK_VO1_S_ROOT_SWITCH_EN — switch_en
    1=ENABLE (Enable pclk_vo1_s_root switched to lower frequency when module is inactive.); 0=DISABLE (Disable auto switch function.)
  [12] PCLK_VO1_S_ROOT_AUTOCS_EN — autocs_en
    1=ENABLE (Enable pclk_vo1_s_root switch to lower frequency.); 0=DISABLE
  [11:0] PCLK_VO1_S_ROOT_AUTOCS_CTRL — autocs_ctrl. Others: Reserved.
    0xFFF=ENABLE (Enable pclk_vo1_s_root switch to lower frequency.); 0=DISABLE
0xEF8 AUTOCS_PCLK_GPU_ROOT_CON0 — Auto clock switch control register 0
  [31:16] PCLK_GPU_ROOT_WAIT_TH — wait_th. Wait time threshold, measured by original clk.
  [15:0] PCLK_GPU_ROOT_IDLE_TH — idle_th. Idle time threshold, measured by original clk.
0xEFC AUTOCS_PCLK_GPU_ROOT_CON1 — Auto clock switch control register 1
  [15:14] PCLK_GPU_ROOT_CLKSEL_CFG — clksel_cfg Auto switch clock selection.
    0=ORIGINAL_CLK; 1=XIN_OSC0_FUNC_DIV; 2=CLK_RTC_32K
  [13] PCLK_GPU_ROOT_SWITCH_EN — switch_en
    1=ENABLE (Enable pclk_gpu_root switched to lower frequency when module is inactive.); 0=DISABLE (Disable auto switch function.)
  [12] PCLK_GPU_ROOT_AUTOCS_EN — autocs_en
    1=ENABLE (Enable pclk_gpu_root switch to lower frequency.); 0=DISABLE
  [11:0] PCLK_GPU_ROOT_AUTOCS_CTRL — autocs_ctrl. Others: Reserved.
    0xFFF=ENABLE (Enable pclk_gpu_root switch to lower frequency.); 0=DISABLE
0xF00 AUTOCS_HCLK_CENTER_ROOT_CON0 — Auto clock switch control register 0
  [31:16] HCLK_CENTER_ROOT_WAIT_TH — wait_th. Wait time threshold, measured by original clk.
  [15:0] HCLK_CENTER_ROOT_IDLE_TH — idle_th. Idle time threshold, measured by original clk.
0xF04 AUTOCS_HCLK_CENTER_ROOT_CON1 — Auto clock switch control register 1
  [15:14] HCLK_CENTER_ROOT_CLKSEL_CFG — clksel_cfg Auto switch clock selection.
    0=ORIGINAL_CLK; 1=XIN_OSC0_FUNC_DIV; 2=CLK_RTC_32K
  [13] HCLK_CENTER_ROOT_SWITCH_EN — switch_en
    1=ENABLE (Enable hclk_center_root switched to lower frequency when module is inactive.); 0=DISABLE (Disable auto switch function.)
  [12] HCLK_CENTER_ROOT_AUTOCS_EN — autocs_en
    1=ENABLE (Enable hclk_center_root switch to lower frequency.); 0=DISABLE
  [11:0] HCLK_CENTER_ROOT_AUTOCS_CTRL — autocs_ctrl. Others: Reserved.
    0xFFF=ENABLE (Enable hclk_center_root switch to lower frequency.); 0=DISABLE
0xF08 AUTOCS_PCLK_CENTER_ROOT_CON0 — Auto clock switch control register 0
  [31:16] PCLK_CENTER_ROOT_WAIT_TH — wait_th. Wait time threshold, measured by original clk.
  [15:0] PCLK_CENTER_ROOT_IDLE_TH — idle_th. Idle time threshold, measured by original clk.
0xF0C AUTOCS_PCLK_CENTER_ROOT_CON1 — Auto clock switch control register 1
  [15:14] PCLK_CENTER_ROOT_CLKSEL_CFG — clksel_cfg Auto switch clock selection.
    0=ORIGINAL_CLK; 1=XIN_OSC0_FUNC_DIV; 2=CLK_RTC_32K
  [13] PCLK_CENTER_ROOT_SWITCH_EN — switch_en
    1=ENABLE (Enable pclk_center_root switched to lower frequency when module is inactive.); 0=DISABLE (Disable auto switch function.)
  [12] PCLK_CENTER_ROOT_AUTOCS_EN — autocs_en
    1=ENABLE (Enable pclk_center_root switch to lower frequency.); 0=DISABLE
  [11:0] PCLK_CENTER_ROOT_AUTOCS_CTRL — autocs_ctrl. Others: Reserved.
    0xFFF=ENABLE (Enable pclk_center_root switch to lower frequency.); 0=DISABLE
0xF10 AUTOCS_ACLK_CENTER_S200_ROOT_CON0 — Auto clock switch control register 0
  [31:16] ACLK_CENTER_S200_ROOT_WAIT_TH — wait_th. Wait time threshold, measured by original clk.
  [15:0] ACLK_CENTER_S200_ROOT_IDLE_TH — idle_th. Idle time threshold, measured by original clk.
0xF14 AUTOCS_ACLK_CENTER_S200_ROOT_CON1 — Auto clock switch control register 1
  [15:14] ACLK_CENTER_S200_ROOT_CLKSEL_CFG — clksel_cfg Auto switch clock selection.
    0=ORIGINAL_CLK; 1=XIN_OSC0_FUNC_DIV; 2=CLK_RTC_32K
  [13] ACLK_CENTER_S200_ROOT_SWITCH_EN — switch_en
    1=ENABLE (Enable aclk_center_s200_root switched to lower frequency when module is inactive.); 0=DISABLE (Disable auto switch function.)
  [12] ACLK_CENTER_S200_ROOT_AUTOCS_EN — autocs_en
    1=ENABLE (Enable aclk_center_s200_root switch to lower frequency.); 0=DISABLE
  [11:0] ACLK_CENTER_S200_ROOT_AUTOCS_CTRL — autocs_ctrl. Others: Reserved.
    0xFFF=ENABLE (Enable aclk_center_s200_root switch to lower frequency.); 0=DISABLE
0xF18 AUTOCS_HCLK_SDIO_ROOT_CON0 — Auto clock switch control register 0
  [31:16] HCLK_SDIO_ROOT_WAIT_TH — wait_th. Wait time threshold, measured by original clk.
  [15:0] HCLK_SDIO_ROOT_IDLE_TH — idle_th. Idle time threshold, measured by original clk.
0xF1C AUTOCS_HCLK_SDIO_ROOT_CON1 — Auto clock switch control register 1
  [15:14] HCLK_SDIO_ROOT_CLKSEL_CFG — clksel_cfg Auto switch clock selection.
    0=ORIGINAL_CLK; 1=XIN_OSC0_FUNC_DIV; 2=CLK_RTC_32K
  [13] HCLK_SDIO_ROOT_SWITCH_EN — switch_en
    1=ENABLE (Enable hclk_sdio_root switched to lower frequency when module is inactive.); 0=DISABLE (Disable auto switch function.)
  [12] HCLK_SDIO_ROOT_AUTOCS_EN — autocs_en
    1=ENABLE (Enable hclk_sdio_root switch to lower frequency.); 0=DISABLE
  [11:0] HCLK_SDIO_ROOT_AUTOCS_CTRL — autocs_ctrl. Others: Reserved.
    0xFFF=ENABLE (Enable hclk_sdio_root switch to lower frequency.); 0=DISABLE
0xF20 AUTOCS_HCLK_RGA3_ROOT_CON0 — Auto clock switch control register 0
  [31:16] HCLK_RGA3_ROOT_WAIT_TH — wait_th. Wait time threshold, measured by original clk.
  [15:0] HCLK_RGA3_ROOT_IDLE_TH — idle_th. Idle time threshold, measured by original clk.
0xF24 AUTOCS_HCLK_RGA3_ROOT_CON1 — Auto clock switch control register 1
  [15:14] HCLK_RGA3_ROOT_CLKSEL_CFG — clksel_cfg Auto switch clock selection.
    0=ORIGINAL_CLK; 1=XIN_OSC0_FUNC_DIV; 2=CLK_RTC_32K
  [13] HCLK_RGA3_ROOT_SWITCH_EN — switch_en
    1=ENABLE (Enable hclk_rga3_root switched to lower frequency when module is inactive.); 0=DISABLE (Disable auto switch function.)
  [12] HCLK_RGA3_ROOT_AUTOCS_EN — autocs_en
    1=ENABLE (Enable hclk_rga3_root switch to lower frequency.); 0=DISABLE
  [11:0] HCLK_RGA3_ROOT_AUTOCS_CTRL — autocs_ctrl. Others: Reserved.
    0xFFF=ENABLE (Enable hclk_rga3_root switch to lower frequency.); 0=DISABLE
0xF28 AUTOCS_HCLK_VO1USB_TOP_ROOT_CON0 — Auto clock switch control register 0
  [31:16] HCLK_VO1USB_TOP_ROOT_WAIT_TH — wait_th. Wait time threshold, measured by original clk.
  [15:0] HCLK_VO1USB_TOP_ROOT_IDLE_TH — idle_th. Idle time threshold, measured by original clk.
0xF2C AUTOCS_HCLK_VO1USB_TOP_ROOT_CON1 — Auto clock switch control register 1
  [15:14] HCLK_VO1USB_TOP_ROOT_CLKSEL_CFG — clksel_cfg Auto switch clock selection.
    0=ORIGINAL_CLK; 1=XIN_OSC0_FUNC_DIV; 2=CLK_RTC_32K
  [13] HCLK_VO1USB_TOP_ROOT_SWITCH_EN — switch_en
    1=ENABLE (Enable hclk_vo1usb_top_root switched to lower frequency when module is inactive.); 0=DISABLE (Disable auto switch function.)
  [12] HCLK_VO1USB_TOP_ROOT_AUTOCS_EN — autocs_en
    1=ENABLE (Enable hclk_vo1usb_top_root switch to lower frequency.); 0=DISABLE
  [11:0] HCLK_VO1USB_TOP_ROOT_AUTOCS_CTRL — autocs_ctrl. Others: Reserved.
    0xFFF=ENABLE (Enable hclk_vo1usb_top_root switch to lower frequency.); 0=DISABLE
0xF30 AUTOCS_ACLK_TOP_M300_ROOT_CON0 — Auto clock switch control register 0
  [31:16] ACLK_TOP_M300_ROOT_WAIT_TH — wait_th. Wait time threshold, measured by original clk.
  [15:0] ACLK_TOP_M300_ROOT_IDLE_TH — idle_th. Idle time threshold, measured by original clk.
0xF34 AUTOCS_ACLK_TOP_M300_ROOT_CON1 — Auto clock switch control register 1
  [15:14] ACLK_TOP_M300_ROOT_CLKSEL_CFG — clksel_cfg Auto switch clock selection.
    0=ORIGINAL_CLK; 1=XIN_OSC0_FUNC_DIV; 2=CLK_RTC_32K
  [13] ACLK_TOP_M300_ROOT_SWITCH_EN — switch_en
    1=ENABLE (Enable aclk_top_m300_root switched to lower frequency when module is inactive.); 0=DISABLE (Disable auto switch function.)
  [12] ACLK_TOP_M300_ROOT_AUTOCS_EN — autocs_en
    1=ENABLE (Enable aclk_top_m300_root switch to lower frequency.); 0=DISABLE
  [11:0] ACLK_TOP_M300_ROOT_AUTOCS_CTRL — autocs_ctrl. Others: Reserved.
    0xFFF=ENABLE (Enable aclk_top_m300_root switch to lower frequency.); 0=DISABLE
0xF38 AUTOCS_CLK_RKNN_DSU0_SRC_T_CON0 — Auto clock switch control register 0
  [31:16] CLK_RKNN_DSU0_SRC_T_WAIT_TH — wait_th. Wait time threshold, measured by original clk.
  [15:0] CLK_RKNN_DSU0_SRC_T_IDLE_TH — idle_th. Idle time threshold, measured by original clk.
0xF3C AUTOCS_CLK_RKNN_DSU0_SRC_T_CON1 — Auto clock switch control register 1
  [15:14] CLK_RKNN_DSU0_SRC_T_CLKSEL_CFG — clksel_cfg Auto switch clock selection.
    0=ORIGINAL_CLK; 1=XIN_OSC0_FUNC_DIV; 2=CLK_RTC_32K
  [13] CLK_RKNN_DSU0_SRC_T_SWITCH_EN — switch_en
    1=ENABLE (Enable clk_rknn_dsu0_src_t switched to lower frequency when module is inactive.); 0=DISABLE (Disable auto switch function.)
  [12] CLK_RKNN_DSU0_SRC_T_AUTOCS_EN — autocs_en
    1=ENABLE (Enable clk_rknn_dsu0_src_t switch to lower frequency.); 0=DISABLE
  [11:0] CLK_RKNN_DSU0_SRC_T_AUTOCS_CTRL — autocs_ctrl. Others: Reserved.
    0xFFF=ENABLE (Enable clk_rknn_dsu0_src_t switch to lower frequency.); 0=DISABLE
0xF40 AUTOCS_HCLK_AUDIO_ROOT_CON0 — Auto clock switch control register 0
  [31:16] HCLK_AUDIO_ROOT_WAIT_TH — wait_th. Wait time threshold, measured by original clk.
  [15:0] HCLK_AUDIO_ROOT_IDLE_TH — idle_th. Idle time threshold, measured by original clk.
0xF44 AUTOCS_HCLK_AUDIO_ROOT_CON1 — Auto clock switch control register 1
  [15:14] HCLK_AUDIO_ROOT_CLKSEL_CFG — clksel_cfg Auto switch clock selection.
    0=ORIGINAL_CLK; 1=XIN_OSC0_FUNC_DIV; 2=CLK_RTC_32K
  [13] HCLK_AUDIO_ROOT_SWITCH_EN — switch_en
    1=ENABLE (Enable hclk_audio_root switched to lower frequency when module is inactive.); 0=DISABLE (Disable auto switch function.)
  [12] HCLK_AUDIO_ROOT_AUTOCS_EN — autocs_en
    1=ENABLE (Enable hclk_audio_root switch to lower frequency.); 0=DISABLE
  [11:0] HCLK_AUDIO_ROOT_AUTOCS_CTRL — autocs_ctrl. Others: Reserved.
    0xFFF=ENABLE (Enable hclk_audio_root switch to lower frequency.); 0=DISABLE
0xF48 AUTOCS_PCLK_AUDIO_ROOT_CON0 — Auto clock switch control register 0
  [31:16] PCLK_AUDIO_ROOT_WAIT_TH — wait_th. Wait time threshold, measured by original clk.
  [15:0] PCLK_AUDIO_ROOT_IDLE_TH — idle_th. Idle time threshold, measured by original clk.
0xF4C AUTOCS_PCLK_AUDIO_ROOT_CON1 — Auto clock switch control register 1
  [15:14] PCLK_AUDIO_ROOT_CLKSEL_CFG — clksel_cfg Auto switch clock selection.
    0=ORIGINAL_CLK; 1=XIN_OSC0_FUNC_DIV; 2=CLK_RTC_32K
  [13] PCLK_AUDIO_ROOT_SWITCH_EN — switch_en
    1=ENABLE (Enable pclk_audio_root switched to lower frequency when module is inactive.); 0=DISABLE (Disable auto switch function.)
  [12] PCLK_AUDIO_ROOT_AUTOCS_EN — autocs_en
    1=ENABLE (Enable pclk_audio_root switch to lower frequency.); 0=DISABLE
  [11:0] PCLK_AUDIO_ROOT_AUTOCS_CTRL — autocs_ctrl. Others: Reserved.
    0xFFF=ENABLE (Enable pclk_audio_root switch to lower frequency.); 0=DISABLE
